# Cortex_M0+ register map
Vendor: ARM Ltd.; Series: M
CPU: CM0P r0p0, little endian, vendor SysTick, 8 interrupt priority bits
Registers are 32-bit, read-write, no defined reset value unless marked. A register's access mark holds for its fields unless they carry their own. Offsets are from the block's base; lines under a group give offsets from that group; [hi:lo] are bit positions; {n}, {i} and the like mark numbered series; 'fields as' and 'values as' point back to an identical list; <NAME> marks a mode.

## Memory map
? Core — Core, the registers are not accessed by address
0xE000E010 SysTick size 0x80 — System Timer registers
0xE000E100 NVIC size 0x1A0 — Nested Vectored Interrupt Controller registers
0xE000ED00 ID size 0x20 — ID registers
0xE000ED04 Control size 0xE0 — System Control registers
0xE000ED90 MPU size 0xA0 — Memory Protection Unit registers

## Core — Core, the registers are not accessed by address
Base ?
? R{i} (i=0..12)
? SP
? LR
? PC
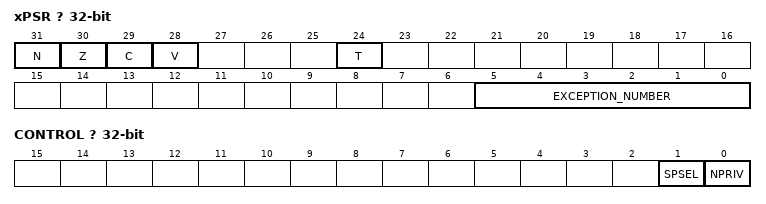
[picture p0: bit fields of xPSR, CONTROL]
? xPSR
  [31] N
  [30] Z — Zero flag
  [29] C
  [28] V
  [24] T
  [5:0] EXCEPTION_NUMBER
    1=Reset; 2=NMI; 3=Hard_Fault; 11=SVCall; 14=PendSV; 15=SysTck; 0=NONE; 16=External_Interrupt_0x00; 17=External_Interrupt_0x01; 18=External_Interrupt_0x02; 19=External_Interrupt_0x03; 20=External_Interrupt_0x04; 21=External_Interrupt_0x05; 22=External_Interrupt_0x06; 23=External_Interrupt_0x07; 24=External_Interrupt_0x08; 25=External_Interrupt_0x09; 26=External_Interrupt_0x0A; 27=External_Interrupt_0x0B; 28=External_Interrupt_0x0C; 29=External_Interrupt_0x0D; 30=External_Interrupt_0x0E; 31=External_Interrupt_0x0F; 32=External_Interrupt_0x10; 33=External_Interrupt_0x11; 34=External_Interrupt_0x12; 35=External_Interrupt_0x13; 36=External_Interrupt_0x14; 37=External_Interrupt_0x15; 38=External_Interrupt_0x16; 39=External_Interrupt_0x17; 40=External_Interrupt_0x18; 41=External_Interrupt_0x19; 42=External_Interrupt_0x1A; 43=External_Interrupt_0x1B; 44=External_Interrupt_0x1C; 45=External_Interrupt_0x1D; 46=External_Interrupt_0x1E; 47=External_Interrupt_0x1F
? PRIMASK
  [0] PM
? CONTROL
  [1] SPSEL
    0=SP_main_in_use; 1=SP_process_in_use
  [0] NPRIV
    0=Privileged_access; 1=Unprivileged_access

## SysTick — System Timer registers
Base 0xE000E010
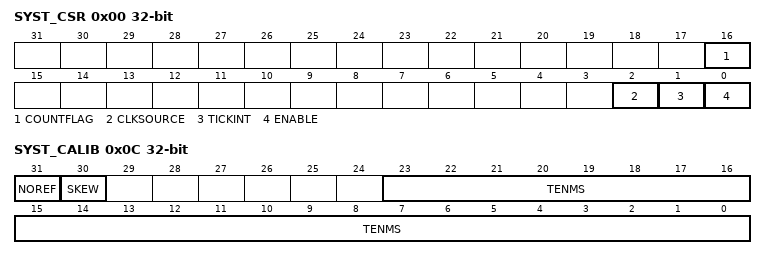
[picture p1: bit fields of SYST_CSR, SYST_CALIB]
0x00 SYST_CSR
  [16] COUNTFLAG
    0=Not_counted_to_0; 1=Counted_to_0
  [2] CLKSOURCE
    0=External_clock; 1=Processor_clock
  [1] TICKINT
    0=Does_not_affect_exception_status; 1=Changes_exception_status
  [0] ENABLE
    0=Counter_disabled; 1=Counter_operating
0x04 SYST_RVR
  [23:0] RELOAD
0x08 SYST_CVR
  [23:0] CURRENT
0x0C SYST_CALIB
  [31] NOREF
    0=Implemented; 1=Not_implemented
  [30] SKEW
    0=Exact; 1=Inexact
  [23:0] TENMS

## Control — System Control registers
Base 0xE000ED04
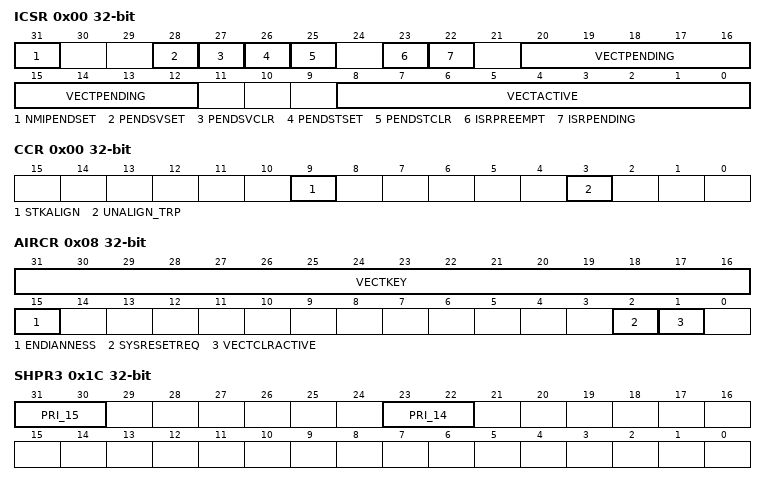
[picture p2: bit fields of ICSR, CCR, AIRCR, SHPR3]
0x00 ICSR
  [31] NMIPENDSET
    0=Do_not_activate; 1=Activate_NMI_exception
  [28] PENDSVSET
    0=Do_not_set; 1=Set_pending
  [27] PENDSVCLR
    0=Do_not_clear; 1=Clear_pending
  [26] PENDSTSET
    0=Do_not_set; 1=Set_pending
  [25] PENDSTCLR
    0=Do_not_clear; 1=Clear_pending
  [23] ISRPREEMPT
    0=Will_not_service; 1=Will_service_pending_exception
  [22] ISRPENDING
    0=Interrupt_not_pending; 1=Interrupt_pending
  [20:12] VECTPENDING
  [8:0] VECTACTIVE
0x00 CCR ro
  [9] STKALIGN, [3] UNALIGN_TRP
0x04 VTOR
  [31:7] TBLOFF
0x08 AIRCR
  [31:16] VECTKEY
  [15] ENDIANNESS
    0=Little_endian; 1=Big_endian
  [2] SYSRESETREQ
    0=Do_not_request_reset; 1=Request_reset
  [1] VECTCLRACTIVE
    0=Do_not_clear; 1=Clear_state_information
0x18 SHPR2
  [31:30] PRI_11
0x1C SHPR3
  [31:30] PRI_15, [23:22] PRI_14
0x20 SHCSR
  [15] SVCALLPENDED
    0=Not_pending; 1=Pending

## ID — ID registers
Base 0xE000ED00
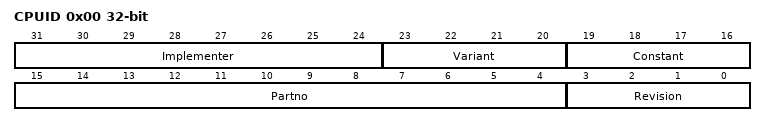
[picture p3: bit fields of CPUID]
0x00 CPUID ro
  [31:24] Implementer, [23:20] Variant, [19:16] Constant, [15:4] Partno, [3:0] Revision

## MPU — Memory Protection Unit registers
Base 0xE000ED90
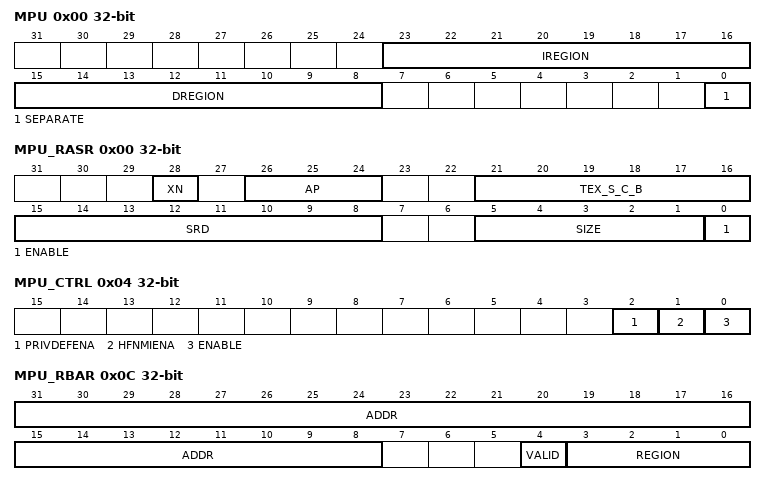
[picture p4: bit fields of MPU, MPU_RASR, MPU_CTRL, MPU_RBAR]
0x00 MPU Type ro
  [23:16] IREGION, [15:8] DREGION, [0] SEPARATE
0x00 MPU_RASR
  [28] XN
    0=Execution_permitted; 1=Execution_not_permitted
  [26:24] AP
    0=No_access; 1=Privileged_RW; 2=Privileged_RW_Unprivileged_RO; 3=Full_access; 5=Privileged_RO; 6=Privileged_RO_Unprivileged_RO; 7=Privileged_RO_Unprivileged_RO
  [21:16] TEX_S_C_B
    0=Strongly_ordered_Shareable; 1=Shared_device; 2=Outer_inner_write_through_No_write_allocate_Not_shareable; 3=Outer_inner_write_back_No_write_allocate_Not_shareable; 4=Strongly_ordered_Shareable_; 5=Shared_device_; 6=Outer_inner_write_through_No_write_allocate_Shareable; 7=Outer_inner_write_back_No_write_allocate_Shareable
  [15:8] SRD
  [5:1] SIZE
    7=_256B; 8=_512B; 9=_1KB; 10=_2KB; 11=_4KB; 12=_8KB; 13=_16KB; 14=_32KB; 15=_64KB; 16=_128KB; 17=_256KB; 18=_512KB; 19=_1MB; 20=_2MB; 21=_4MB; 22=_8MB; 23=_16MB; 24=_32MB; 25=_64MB; 26=_128MB; 27=_256MB; 28=_512MB; 29=_1GB; 30=_2GB; 31=_4GB
  [0] ENABLE
    0=Disabled; 1=Enabled
0x04 MPU_CTRL
  [all] fields
    0=Disabled; 1=Enabled
  [2] PRIVDEFENA
  [1] HFNMIENA
  [0] ENABLE
0x08 MPU_RNR
  [7:0] REGION
0x0C MPU_RBAR
  [31:8] ADDR, [4] VALID, [3:0] REGION

## NVIC — Nested Vectored Interrupt Controller registers
Base 0xE000E100
0x00 NVIC_ISER0
0x00 NVIC_ISPR0
0x80 NVIC_ICER0
0x180 NVIC_ICPR0
0x200 NVIC_IABR0
{0x300+4i} NVIC_IPR{i} (i=0..7)
